# CM55F register map
Registers are read-write, no defined reset value unless marked. A register's access mark holds for its fields unless they carry their own. Offsets are from the block's base; [hi:lo] are bit positions; {n}, {i} and the like mark numbered series; 'fields as' and 'values as' point back to an identical list.

## DCA — Direct Cache Access
Base 0xE001E200
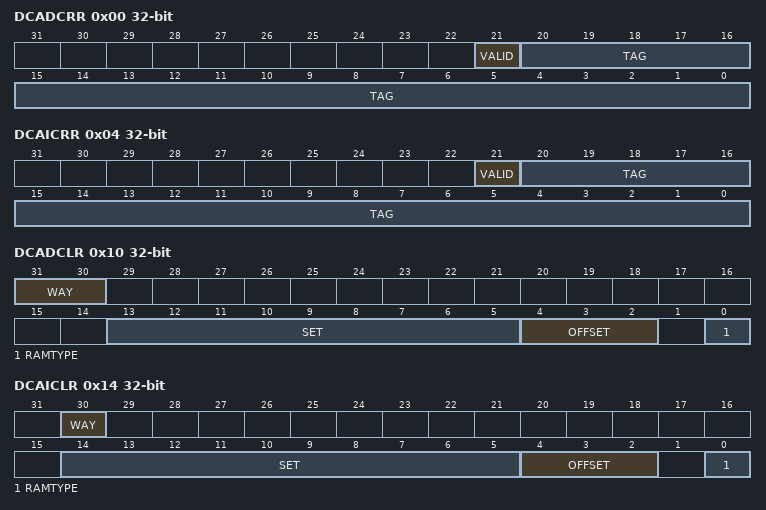
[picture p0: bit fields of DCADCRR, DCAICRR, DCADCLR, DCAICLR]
0x00 DCADCRR ro — Direct Data Cache Access Read Registers read the data from the Level 1 (L1) data cache from the location that is determined by the DCADCLR registers
  [21] VALID — Valid state of the cache line
  [20:0] TAG — Tag address. The number of significant bits of TAG depends on the cache size.
0x04 DCAICRR ro — Direct Instruction Cache Access Read Registers read the data from the Level 1 (L1) instruction cache from the location that is determined by the DCAICLR registers
  fields as DCADCRR
0x10 DCADCLR — Direct Data Cache Access Location Registers set the location to be read from the Level 1 (L1) data cache
  [31:30] WAY — Cache way
  [13:5] SET — Set index. The number of significant bits of SET depends on the cache size.
  [4:2] OFFSET — Data offset
  [0] RAMTYPE
    0=Tag RAM; 1=Data RAM
0x14 DCAICLR — Direct Instruction Cache Access Location Registers set the location to be read from the Level 1 (L1) instruction cache
  [30] WAY — Cache way
  [14:5] SET — Set index. The number of significant bits of SET depends on the cache size.
  [4:2] OFFSET — Data offset
  [0] RAMTYPE
    0=Tag RAM; 1=Data RAM

## ERRBNK — Implementation defined error banking
Base 0xE001E100
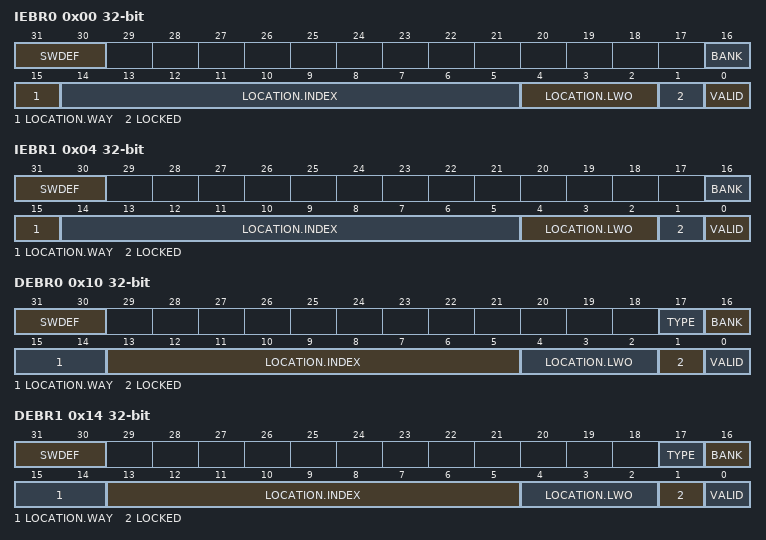
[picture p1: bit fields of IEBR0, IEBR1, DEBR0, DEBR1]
0x00 IEBR0 — Instruction Cache Error Bank Register record errors that occur during memory accesses to the L1 instruction cache
  [31:30] SWDEF — Error detection logic sets this field to 0b00 on a new allocation and on Cold reset
  [16] BANK — Indicates which RAM bank to use
    0=Tag RAM; 1=Data RAM
  [15] LOCATION.WAY — Indicates the location in the L1 instruction cache RAM, way
  [14:5] LOCATION.INDEX — Indicates the location in the L1 instruction cache RAM, index
  [4:2] LOCATION.LWO — Indicates the location in the L1 instruction cache RAM, line word offset
  [1] LOCKED — Indicates whether the location is locked or not
    0=Location is not locked and available for hardware to allocate; 1=Software has locked the location and hardware is not allowed to allocate to this entry
  [0] VALID — Indicates whether the entry is valid or not
    0=Entry is invalid; 1=Entry is valid
0x04 IEBR1 — Instruction Cache Error Bank Register record errors that occur during memory accesses to the L1 instruction cache
  fields as IEBR0
0x10 DEBR0 — Data Cache Error Bank Register record errors that occur during memory accesses to the L1 data cache
  [31:30] SWDEF — Error detection logic sets this field to 0b00 on a new allocation and on Cold reset
  [17] TYPE — Indicates the error type
    0=Single-bit error; 1=Multi-bit error
  [16] BANK — Indicates which RAM bank to use
    0=Tag RAM; 1=Data RAM
  [15:14] LOCATION.WAY — Indicates the location in the L1 instruction cache RAM, way
  [13:5] LOCATION.INDEX — Indicates the location in the L1 instruction cache RAM, index
  [4:2] LOCATION.LWO — Indicates the location in the L1 instruction cache RAM, line doubleword offset
  [1] LOCKED — Indicates whether the location is locked or not
    values as IEBR0.LOCKED
  [0] VALID — Indicates whether the entry is valid or not
    0=Entry is invalid; 1=Entry is valid
0x14 DEBR1 — Data Cache Error Bank Register record errors that occur during memory accesses to the L1 data cache
  fields as DEBR0
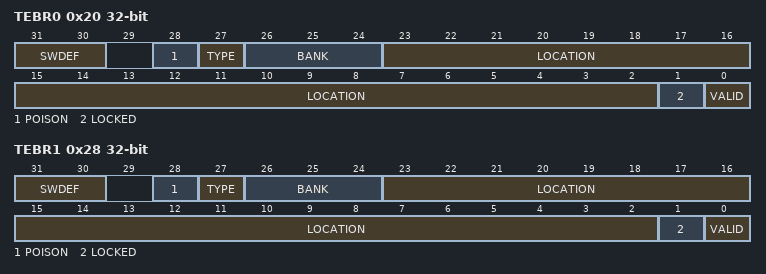
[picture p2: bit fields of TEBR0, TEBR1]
0x20 TEBR0 — TCM Error Bank Register record the location of errors in the TCM
  [31:30] SWDEF — Error detection logic sets this field to 0b00 on a new allocation and on Cold reset
  [28] POISON — Indicates whether a BusFault is generated or not
    0=Load or non-word store to an address that hits this TEBR gets a BusFault; 1=Load or non-word store to an address that hits this TEBR accesses the corresponding TEBRDATA register and does not get a BusFault
  [27] TYPE — Indicates the error type
    0=Single-bit error; 1=Multi-bit error
  [26:24] BANK — Indicates which RAM bank to use
    {v}=DTCM{v} (v=0..3); 4=ITCM
  [23:2] LOCATION — Indicates the physical location in the data cache RAM
  [1] LOCKED — Indicates whether the location is locked or not
    values as IEBR0.LOCKED
  [0] VALID — Indicates whether the entry is valid or not
    0=Entry is invalid; 1=Entry is valid
0x24 TEBRDATA0 ro — Data for TCU Error Bank Register 0 provides storage for corrected data that is associated with an error
0x28 TEBR1 — TCM Error Bank Register 1 record the location of errors in the TCM
  fields as TEBR0
0x2C TEBRDATA1 ro — Data for TCU Error Bank Register 1 provides storage for corrected data that is associated with an error
